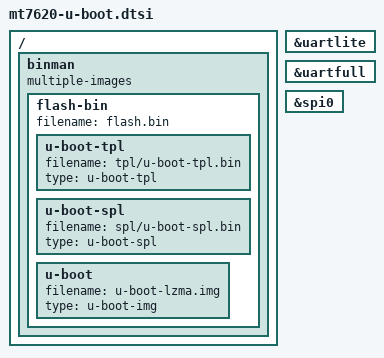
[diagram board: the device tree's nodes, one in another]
// SPDX-License-Identifier: GPL-2.0
/*
 * Copyright (C) 2020 MediaTek Inc.
 *
 * Author: Weijie Gao <weijie.gao@mediatek.com>
 */

#include <linux/stringify.h>

/ {
	binman: binman {
		multiple-images;
	};
};

&uartlite {
	bootph-all;
};

&uartfull {
	bootph-all;
};

&spi0 {
	bootph-all;
};

&binman {

	flash-bin {
		filename = "flash.bin";

		u-boot-tpl {
			filename = "tpl/u-boot-tpl.bin";
			type = "u-boot-tpl";
//			entry = <CONFIG_SPL_TEXT_BASE>;
		};

		u-boot-spl {
			filename = "spl/u-boot-spl.bin";
			type = "u-boot-spl";
		};

		u-boot {
			filename = "u-boot-lzma.img";
			type = "u-boot-img";
		};
	};
};
